# XMC4200 register map
Vendor: Infineon; File version: 1.5.2 (Reference Manual v1.5)
CPU: CM4 r2p0, little endian, MPU, FPU, 6 interrupt priority bits
Registers are 32-bit, read-write, reset 0x0 unless marked. A register's access mark holds for its fields unless they carry their own. Offsets are from the block's base; [hi:lo] are bit positions; 'fields as' and 'values as' point back to an identical list.

## SCU_POWER — System Control Unit
Base 0x50004200
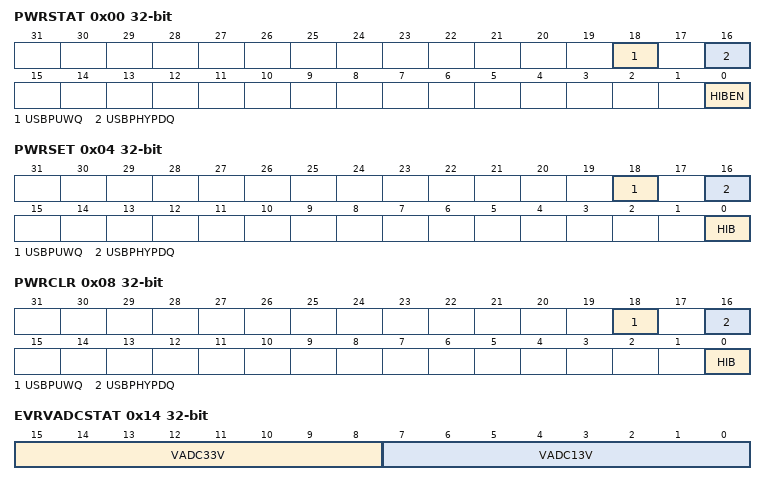
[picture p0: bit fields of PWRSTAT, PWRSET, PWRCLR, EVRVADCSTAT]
0x00 PWRSTAT ro — PCU Status Register
  [18] USBPUWQ — USB Weak Pull-Up at PADN State
    0=Pull-up active; 1=Pull-up not active
  [16] USBPHYPDQ — USB PHY Transceiver State
    0=Power-down; 1=Active
  [0] HIBEN — Hibernate Domain Enable Status
    0=Inactive; 1=Active
0x04 PWRSET wo — PCU Set Control Register
  [18] USBPUWQ — Set USB Weak Pull-Up at PADN Enable
    0=No effect; 1=Pull-up not active
  [16] USBPHYPDQ — Set USB PHY Transceiver Disable
    0=No effect; 1=Active
  [0] HIB — Set Hibernate Domain Enable
    0=No effect; 1=Enable Hibernate domain
0x08 PWRCLR wo — PCU Clear Control Register
  [18] USBPUWQ — Clear USB Weak Pull-Up at PADN Enable
    0=No effect; 1=Pull-up active
  [16] USBPHYPDQ — Clear USB PHY Transceiver Disable
    0=No effect; 1=Power-down
  [0] HIB — Clear Disable Hibernate Domain
    0=No effect; 1=Disable Hibernate domain
0x10 EVRSTAT ro — EVR Status Register
  [1] OV13 — Regulator Overvoltage for 1.3 V
    0=No overvoltage condition; 1=Regulator is in overvoltage
0x14 EVRVADCSTAT ro — EVR VADC Status Register
  [15:8] VADC33V — VADC 3.3 V Conversion Result
  [7:0] VADC13V — VADC 1.3 V Conversion Result
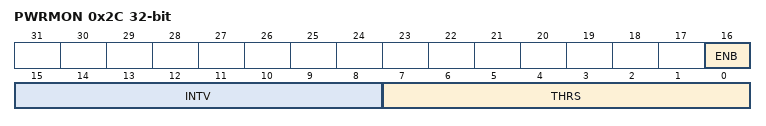
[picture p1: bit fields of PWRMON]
0x2C PWRMON — Power Monitor Control
  [16] ENB — Enable
  [15:8] INTV — Interval
  [7:0] THRS — Threshold

## USB0_EP0 — Universal Serial Bus
Base 0x50040900
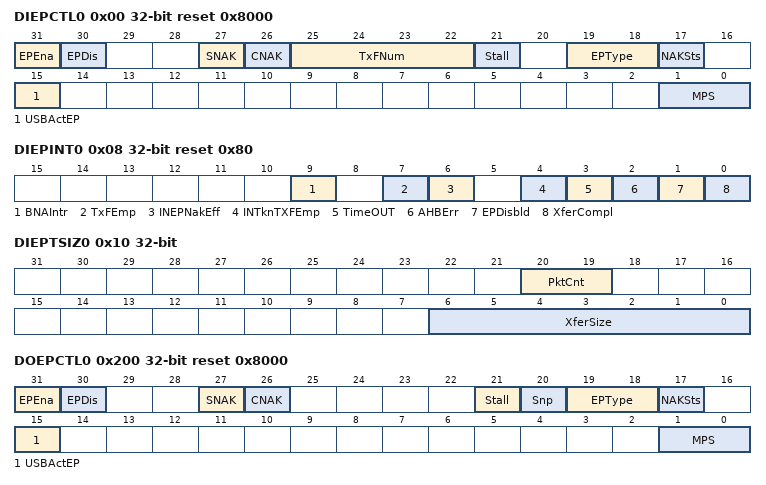
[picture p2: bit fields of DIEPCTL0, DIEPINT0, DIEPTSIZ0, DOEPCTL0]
0x00 DIEPCTL0 access per field reset 0x8000 — Device Control IN Endpoint Control Register
  [31] EPEna rw — Endpoint Enable
  [30] EPDis rw — Endpoint Disable
  [27] SNAK wo — Set NAK
  [26] CNAK wo — Clear NAK
  [25:22] TxFNum rw — TxFIFO Number
  [21] Stall rw — STALL Handshake
  [19:18] EPType ro — Endpoint Type
  [17] NAKSts ro — NAK Status
    0=The core is transmitting non-NAK handshakes based on the FIFO status; 1=The core is transmitting NAK handshakes on this endpoint
  [15] USBActEP ro — USB Active Endpoint
  [1:0] MPS rw — Maximum Packet Size
    0=64 bytes; 1=32 bytes; 2=16 bytes; 3=8 bytes
0x08 DIEPINT0 access per field reset 0x80 — Device Endpoint Interrupt Register
  [9] BNAIntr rw — BNA (Buffer Not Available) Interrupt
  [7] TxFEmp ro — Transmit FIFO Empty
  [6] INEPNakEff rw — IN Endpoint NAK Effective
  [4] INTknTXFEmp rw — IN Token Received When TxFIFO is Empty
  [3] TimeOUT rw — Timeout Condition
  [2] AHBErr rw — AHB Error
  [1] EPDisbld rw — Endpoint Disabled Interrupt
  [0] XferCompl rw — Transfer Completed Interrupt
0x10 DIEPTSIZ0 — Device IN Endpoint Transfer Size Register
  [20:19] PktCnt — Packet Count
  [6:0] XferSize — Transfer Size
0x14 DIEPDMA0 reset not defined read-has-side-effects — Device Endpoint DMA Address Register
  [31:0] DMAAddr — DMA Address
0x18 DTXFSTS0 ro — Device IN Endpoint Transmit FIFO Status Register
  [15:0] INEPTxFSpcAvail — IN Endpoint TxFIFO Space Avail
    0=Endpoint TxFIFO is full; 1=1 word available; 2=2 words available
0x1C DIEPDMAB0 ro reset not defined — Device Endpoint DMA Buffer Address Register
  [31:0] DMABufferAddr — DMA Buffer Address
0x200 DOEPCTL0 access per field reset 0x8000 — Device Control OUT Endpoint Control Register
  [31] EPEna rw — Endpoint Enable
  [30] EPDis ro — Endpoint Disable
  [27] SNAK wo — Set NAK
  [26] CNAK wo — Clear NAK
  [21] Stall rw — STALL Handshake
  [20] Snp rw — Snoop Mode
  [19:18] EPType ro — Endpoint Type
  [17] NAKSts ro — NAK Status
    values as DIEPCTL0.NAKSts
  [15] USBActEP ro — USB Active Endpoint
  [1:0] MPS ro — Maximum Packet Size
    0=64 bytes; 1=32 bytes; 2=16 bytes; 3=8 bytes
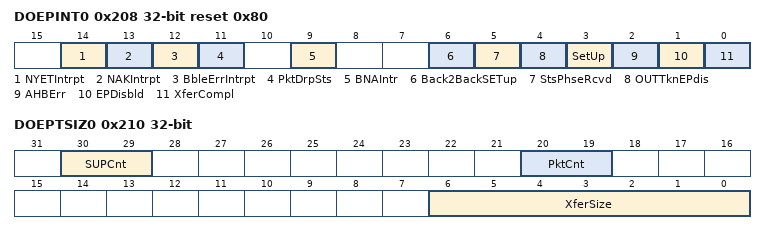
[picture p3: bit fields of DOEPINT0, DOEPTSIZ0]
0x208 DOEPINT0 reset 0x80 — Device Endpoint Interrupt Register
  [14] NYETIntrpt — NYET interrupt
  [13] NAKIntrpt — NAK interrupt
  [12] BbleErrIntrpt — BbleErr (Babble Error) interrupt
  [11] PktDrpSts — Packet Dropped Status
  [9] BNAIntr — BNA (Buffer Not Available) Interrupt
  [6] Back2BackSETup — Back-to-Back SETUP Packets Received
  [5] StsPhseRcvd — Status Phase Received For Control Write
  [4] OUTTknEPdis — OUT Token Received When Endpoint Disabled
  [3] SetUp — SETUP Phase Done
  [2] AHBErr — AHB Error
  [1] EPDisbld — Endpoint Disabled Interrupt
  [0] XferCompl — Transfer Completed Interrupt
0x210 DOEPTSIZ0 — Device OUT Endpoint Transfer Size Register
  [30:29] SUPCnt — SETUP Packet Count
    1=1 packet; 2=2 packets; 3=3 packets
  [20:19] PktCnt — Packet Count
  [6:0] XferSize — Transfer Size
0x214 DOEPDMA0 reset not defined read-has-side-effects — Device Endpoint DMA Address Register
  [31:0] DMAAddr — DMA Address
0x21C DOEPDMAB0 ro reset not defined — Device Endpoint DMA Buffer Address Register
  [31:0] DMABufferAddr — DMA Buffer Address

## Notices in the file
Copyright (C) 2016 Infineon Technologies AG. All rights reserved.
Infineon Technologies AG (Infineon) is supplying this software for use with
Infineon's microcontrollers.  This file can be freely distributed within
development tools that are supporting such microcontrollers.
THIS SOFTWARE IS PROVIDED "AS IS".  NO WARRANTIES, WHETHER EXPRESS, IMPLIED
OR STATUTORY, INCLUDING, BUT NOT LIMITED TO, IMPLIED WARRANTIES OF
MERCHANTABILITY AND FITNESS FOR A PARTICULAR PURPOSE APPLY TO THIS SOFTWARE.
INFINEON SHALL NOT, IN ANY CIRCUMSTANCES, BE LIABLE FOR SPECIAL, INCIDENTAL,
OR CONSEQUENTIAL DAMAGES, FOR ANY REASON WHATSOEVER.
